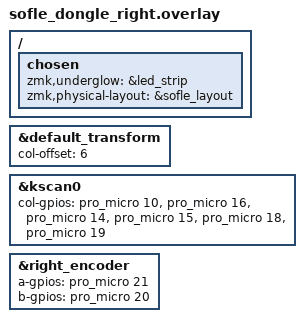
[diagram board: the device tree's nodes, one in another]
/*
 * Copyright (c) 2020 Ryan Cross
 *
 * SPDX-License-Identifier: MIT
 */

#include "sofle_dongle.dtsi"

&default_transform {
    col-offset = <6>;
};

&kscan0 {
    col-gpios
        = <&pro_micro 10 GPIO_ACTIVE_HIGH>
        , <&pro_micro 16 GPIO_ACTIVE_HIGH>
        , <&pro_micro 14 GPIO_ACTIVE_HIGH>
        , <&pro_micro 15 GPIO_ACTIVE_HIGH>
        , <&pro_micro 18 GPIO_ACTIVE_HIGH>
        , <&pro_micro 19 GPIO_ACTIVE_HIGH>
        ;
};

&right_encoder {
    status = "okay";
    // ALTERAÇÃO: Invertido pinos A e B para corrigir sentido do encoder
    a-gpios = <&pro_micro 21 (GPIO_ACTIVE_HIGH | GPIO_PULL_UP)>;
    b-gpios = <&pro_micro 20 (GPIO_ACTIVE_HIGH | GPIO_PULL_UP)>;
};

// ALTERAÇÃO: Habilita RGB underglow e layout físico no lado direito (baseado no zmk-for-keyboards)
/ {
    chosen {
        zmk,underglow = &led_strip;
        zmk,physical-layout = &sofle_layout;
    };
};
